# LM3S6965 register map
Vendor: Texas Instruments; File version: 0.1.0
HAIR extraction for the Texas Instruments LM3S6965 with core structure, physical pin/routing facts, and Embassy HAL profile coverage limited to the evidence-backed first-cut subset requested for lm3s6965evb.
CPU: Cortex-M3 r2p2, little endian, MPU, no FPU, VTOR, 3 interrupt priority bits
Registers are 32-bit, read-write, no defined reset value unless marked. A register's access mark holds for its fields unless they carry their own. Offsets are from the block's base; lines under a group give offsets from that group; [hi:lo] are bit positions; {n}, {i} and the like mark numbered series; 'fields as' and 'values as' point back to an identical list; <NAME> marks a mode.

## Memory map
0x40000000 WATCHDOG0 size 0x1000 — 32-bit watchdog timer with first-timeout interrupt and second-timeout reset support.
0x40004000 GPIOA size 0x1000 — General-purpose I/O port A.
0x40005000 GPIOB size 0x1000 — General-purpose I/O port B.
0x40006000 GPIOC size 0x1000 — General-purpose I/O port C.
0x40007000 GPIOD size 0x1000 — General-purpose I/O port D.
0x40008000 SSI0 size 0x1000 — Synchronous serial interface 0.
0x4000C000 UART0 size 0x1000 — Universal asynchronous receiver/transmitter 0.
0x4000D000 UART1 size 0x1000 — Universal asynchronous receiver/transmitter 1.
0x40020000 I2C0 size 0x1000 — Inter-integrated circuit controller 0 with master and slave sub-blocks.
0x40024000 GPIOE size 0x1000 — General-purpose I/O port E.
0x40025000 GPIOF size 0x1000 — General-purpose I/O port F.
0x40030000 TIMER0 size 0x1000 — General-purpose timer module 0 with Timer A and Timer B halves.
0x40031000 TIMER1 size 0x1000 — General-purpose timer module 1 with Timer A and Timer B halves.
0x40032000 TIMER2 size 0x1000 — General-purpose timer module 2 with Timer A and Timer B halves.
0x40033000 TIMER3 size 0x1000 — General-purpose timer module 3 with Timer A and Timer B halves.
0x400FD000 FLASH_CTRL size 0x1000 — Flash memory control block.
0x400FE000 SYSCTL size 0x1000 — System control block for clocks, resets, device capabilities, and reset causes.
0xE000E010 SysTick size 0x10 — Cortex-M3 system timer.
0xE000E100 NVIC size 0x7D0 — Nested Vectored Interrupt Controller within the Cortex-M3 private peripheral block.

## Interrupts
0 GPIOA — GPIO Port A interrupt.
1 GPIOB — GPIO Port B interrupt.
2 GPIOC — GPIO Port C interrupt.
3 GPIOD — GPIO Port D interrupt.
4 GPIOE — GPIO Port E interrupt.
5 UART0 — UART0 interrupt.
6 UART1 — UART1 interrupt.
7 SSI0 — SSI0 interrupt.
8 I2C0 — I2C0 interrupt.
18 WATCHDOG0 — Watchdog timer interrupt.
19 TIMER0A (TIMER0) — Timer0A interrupt.
20 TIMER0B (TIMER0) — Timer0B interrupt.
21 TIMER1A (TIMER1) — Timer1A interrupt.
22 TIMER1B (TIMER1) — Timer1B interrupt.
23 TIMER2A (TIMER2) — Timer2A interrupt.
24 TIMER2B (TIMER2) — Timer2B interrupt.
28 SYSCTL — System control interrupt.
29 FLASH_CTRL — Flash controller interrupt.
30 GPIOF — GPIO Port F interrupt.
35 TIMER3A (TIMER3) — Timer3A interrupt.
36 TIMER3B (TIMER3) — Timer3B interrupt.

## NVIC — Nested Vectored Interrupt Controller within the Cortex-M3 private peripheral block.
Base 0xE000E100
{0x0+4i} ISER{i} (i=0..1) — Interrupt Set-Enable Registers.
{0x80+4i} ICER{i} (i=0..1) — Interrupt Clear-Enable Registers.
{0x100+4i} ISPR{i} (i=0..1) — Interrupt Set-Pending Registers.
{0x180+4i} ICPR{i} (i=0..1) — Interrupt Clear-Pending Registers.
{0x200+4i} IABR{i} (i=0..1) ro — Interrupt Active Bit Registers.
{0x300+4i} IPR{i} (i=0..11) — Interrupt Priority Registers.

## SysTick — Cortex-M3 system timer.
Base 0xE000E010
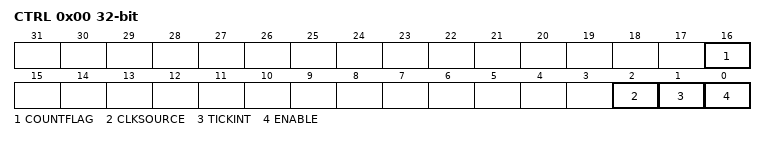
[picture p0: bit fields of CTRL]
0x00 CTRL — SysTick control and status.
  [16] COUNTFLAG ro — Wrap-to-zero status flag.
  [2] CLKSOURCE — Clock source select.
  [1] TICKINT — SysTick interrupt enable.
  [0] ENABLE — Counter enable.
0x04 LOAD — SysTick reload value.
  [23:0] RELOAD — 24-bit reload value.
0x08 VAL — SysTick current value.
  [23:0] CURRENT — 24-bit current count value.
0x0C CALIB ro — SysTick calibration value.
